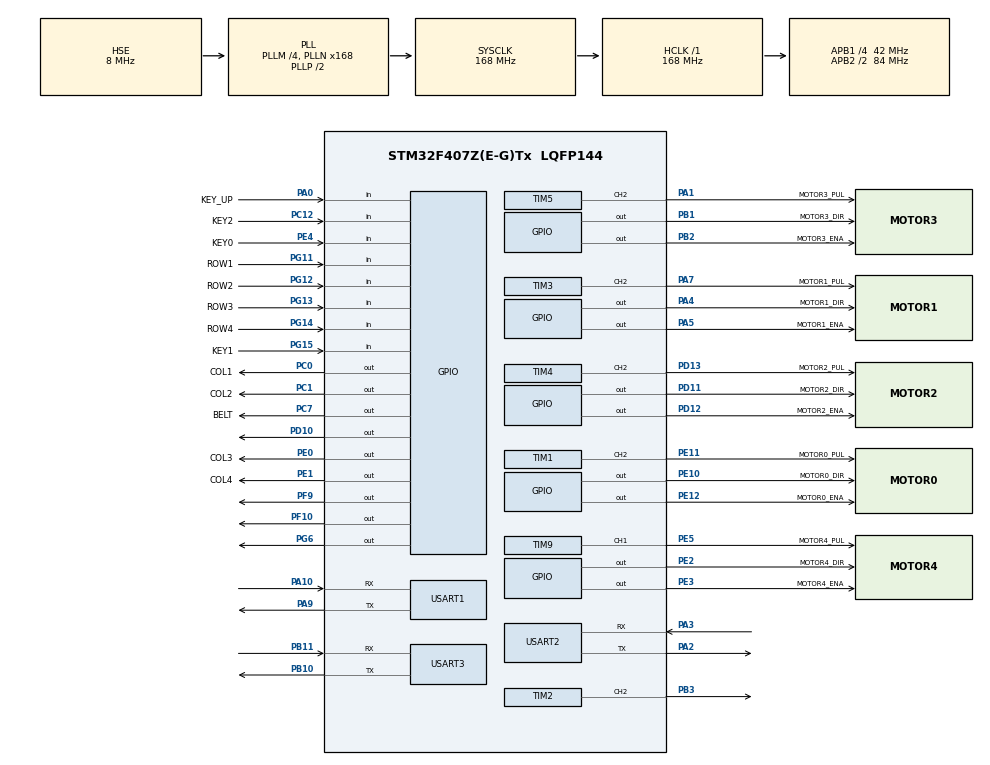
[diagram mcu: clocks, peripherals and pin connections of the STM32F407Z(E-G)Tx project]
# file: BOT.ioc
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Dma.Request0=USART1_RX
Dma.Request1=USART1_TX
Dma.Request2=USART2_RX
Dma.Request3=USART2_TX
Dma.Request4=USART3_RX
Dma.Request5=USART3_TX
Dma.USART1_RX.0.Direction=DMA_PERIPH_TO_MEMORY
Dma.USART1_RX.0.FIFOMode=DMA_FIFOMODE_DISABLE
Dma.USART1_RX.0.Instance=DMA2_Stream2
Dma.USART1_RX.0.MemDataAlignment=DMA_MDATAALIGN_BYTE
Dma.USART1_RX.0.MemInc=DMA_MINC_ENABLE
Dma.USART1_RX.0.Mode=DMA_CIRCULAR
Dma.USART1_RX.0.PeriphDataAlignment=DMA_PDATAALIGN_BYTE
Dma.USART1_RX.0.PeriphInc=DMA_PINC_DISABLE
Dma.USART1_RX.0.Priority=DMA_PRIORITY_VERY_HIGH
Dma.USART1_TX.1.Direction=DMA_MEMORY_TO_PERIPH
Dma.USART1_TX.1.FIFOMode=DMA_FIFOMODE_DISABLE
Dma.USART1_TX.1.Instance=DMA2_Stream7
Dma.USART1_TX.1.MemDataAlignment=DMA_MDATAALIGN_BYTE
Dma.USART1_TX.1.MemInc=DMA_MINC_ENABLE
Dma.USART1_TX.1.Mode=DMA_NORMAL
Dma.USART1_TX.1.PeriphDataAlignment=DMA_PDATAALIGN_BYTE
Dma.USART1_TX.1.PeriphInc=DMA_PINC_DISABLE
Dma.USART1_TX.1.Priority=DMA_PRIORITY_VERY_HIGH
Dma.USART2_RX.2.Direction=DMA_PERIPH_TO_MEMORY
Dma.USART2_RX.2.FIFOMode=DMA_FIFOMODE_DISABLE
Dma.USART2_RX.2.Instance=DMA1_Stream5
Dma.USART2_RX.2.MemDataAlignment=DMA_MDATAALIGN_BYTE
Dma.USART2_RX.2.MemInc=DMA_MINC_ENABLE
Dma.USART2_RX.2.Mode=DMA_NORMAL
Dma.USART2_RX.2.PeriphDataAlignment=DMA_PDATAALIGN_BYTE
Dma.USART2_RX.2.PeriphInc=DMA_PINC_DISABLE
Dma.USART2_RX.2.Priority=DMA_PRIORITY_HIGH
Dma.USART2_TX.3.Direction=DMA_MEMORY_TO_PERIPH
Dma.USART2_TX.3.FIFOMode=DMA_FIFOMODE_DISABLE
Dma.USART2_TX.3.Instance=DMA1_Stream6
Dma.USART2_TX.3.MemDataAlignment=DMA_MDATAALIGN_BYTE
Dma.USART2_TX.3.MemInc=DMA_MINC_ENABLE
Dma.USART2_TX.3.Mode=DMA_NORMAL
Dma.USART2_TX.3.PeriphDataAlignment=DMA_PDATAALIGN_BYTE
Dma.USART2_TX.3.PeriphInc=DMA_PINC_DISABLE
Dma.USART2_TX.3.Priority=DMA_PRIORITY_HIGH
Dma.USART3_RX.4.Direction=DMA_PERIPH_TO_MEMORY
Dma.USART3_RX.4.FIFOMode=DMA_FIFOMODE_DISABLE
Dma.USART3_RX.4.Instance=DMA1_Stream1
Dma.USART3_RX.4.MemDataAlignment=DMA_MDATAALIGN_BYTE
Dma.USART3_RX.4.MemInc=DMA_MINC_ENABLE
Dma.USART3_RX.4.Mode=DMA_NORMAL
Dma.USART3_RX.4.PeriphDataAlignment=DMA_PDATAALIGN_BYTE
Dma.USART3_RX.4.PeriphInc=DMA_PINC_DISABLE
Dma.USART3_RX.4.Priority=DMA_PRIORITY_MEDIUM
Dma.USART3_TX.5.Direction=DMA_MEMORY_TO_PERIPH
Dma.USART3_TX.5.FIFOMode=DMA_FIFOMODE_DISABLE
Dma.USART3_TX.5.Instance=DMA1_Stream3
Dma.USART3_TX.5.MemDataAlignment=DMA_MDATAALIGN_BYTE
Dma.USART3_TX.5.MemInc=DMA_MINC_ENABLE
Dma.USART3_TX.5.Mode=DMA_NORMAL
Dma.USART3_TX.5.PeriphDataAlignment=DMA_PDATAALIGN_BYTE
Dma.USART3_TX.5.PeriphInc=DMA_PINC_DISABLE
Dma.USART3_TX.5.Priority=DMA_PRIORITY_MEDIUM
Mcu.Family=STM32F4
Mcu.Name=STM32F407Z(E-G)Tx
Mcu.Package=LQFP144
NVIC.DMA1_Stream1_IRQn=true\:0\:0\:false\:false\:true\:false\:true\:true
NVIC.DMA1_Stream3_IRQn=true\:0\:0\:false\:false\:true\:false\:true\:true
NVIC.DMA1_Stream5_IRQn=true\:0\:0\:false\:false\:true\:false\:true\:true
NVIC.DMA1_Stream6_IRQn=true\:0\:0\:false\:false\:true\:false\:true\:true
NVIC.DMA2_Stream2_IRQn=true\:0\:0\:false\:false\:true\:false\:true\:true
NVIC.DMA2_Stream7_IRQn=true\:0\:0\:false\:false\:true\:false\:true\:true
NVIC.PriorityGroup=NVIC_PRIORITYGROUP_4
NVIC.TIM1_BRK_TIM9_IRQn=true\:0\:0\:false\:false\:true\:true\:true\:true
NVIC.TIM1_CC_IRQn=true\:0\:0\:false\:false\:true\:true\:true\:true
NVIC.TIM1_TRG_COM_TIM11_IRQn=true\:0\:0\:false\:false\:true\:true\:true\:true
NVIC.TIM1_UP_TIM10_IRQn=true\:0\:0\:false\:false\:true\:true\:true\:true
NVIC.TIM2_IRQn=true\:0\:0\:false\:false\:true\:true\:true\:true
NVIC.TIM3_IRQn=true\:0\:0\:false\:false\:true\:true\:true\:true
NVIC.TIM4_IRQn=true\:0\:0\:false\:false\:true\:true\:true\:true
NVIC.TIM5_IRQn=true\:0\:0\:false\:false\:true\:true\:true\:true
NVIC.USART1_IRQn=true\:0\:0\:false\:false\:true\:true\:true\:true
NVIC.USART2_IRQn=true\:0\:0\:false\:false\:true\:true\:true\:true
NVIC.USART3_IRQn=true\:0\:0\:false\:false\:true\:true\:true\:true
PA0-WKUP.GPIO_Label=KEY_UP
PA0-WKUP.GPIO_PuPd=GPIO_PULLDOWN
PA0-WKUP.Signal=GPIO_Input
PA1.GPIO_Label=MOTOR3_PUL
PA1.Signal=S_TIM5_CH2
PA10.Mode=Asynchronous
PA10.Signal=USART1_RX
PA2.Mode=Asynchronous
PA2.Signal=USART2_TX
PA3.Mode=Asynchronous
PA3.Signal=USART2_RX
PA4.GPIO_Label=MOTOR1_DIR
PA4.GPIO_Speed=GPIO_SPEED_FREQ_LOW
PA4.Signal=GPIO_Output
PA5.GPIO_Label=MOTOR1_ENA
PA5.Signal=GPIO_Output
PA7.GPIO_Label=MOTOR1_PUL
PA7.Signal=S_TIM3_CH2
PA9.Mode=Asynchronous
PA9.Signal=USART1_TX
PB1.GPIO_Label=MOTOR3_DIR
PB1.Signal=GPIO_Output
PB10.Mode=Asynchronous
PB10.Signal=USART3_TX
PB11.Mode=Asynchronous
PB11.Signal=USART3_RX
PB2.GPIO_Label=MOTOR3_ENA
PB2.Signal=GPIO_Output
PB3.Signal=S_TIM2_CH2
PC0.GPIO_Label=COL1
PC0.GPIO_Speed=GPIO_SPEED_FREQ_HIGH
PC0.Signal=GPIO_Output
PC1.GPIO_Label=COL2
PC1.GPIO_Speed=GPIO_SPEED_FREQ_HIGH
PC1.Signal=GPIO_Output
PC12.GPIO_Label=KEY2
PC12.Signal=GPIO_Input
PC7.GPIO_Label=BELT
PC7.Signal=GPIO_Output
PD10.Signal=GPIO_Output
PD11.GPIO_Label=MOTOR2_DIR
PD11.Signal=GPIO_Output
PD12.GPIO_Label=MOTOR2_ENA
PD12.Signal=GPIO_Output
PD13.GPIO_Label=MOTOR2_PUL
PD13.Signal=S_TIM4_CH2
PE0.GPIO_Label=COL3
PE0.GPIO_Speed=GPIO_SPEED_FREQ_HIGH
PE0.Signal=GPIO_Output
PE1.GPIO_Label=COL4
PE1.GPIO_Speed=GPIO_SPEED_FREQ_HIGH
PE1.Signal=GPIO_Output
PE10.GPIO_Label=MOTOR0_DIR
PE10.Signal=GPIO_Output
PE11.GPIO_Label=MOTOR0_PUL
PE11.Signal=S_TIM1_CH2
PE12.GPIO_Label=MOTOR0_ENA
PE12.Signal=GPIO_Output
PE2.GPIO_Label=MOTOR4_DIR
PE2.Signal=GPIO_Output
PE3.GPIO_Label=MOTOR4_ENA
PE3.Signal=GPIO_Output
PE4.GPIO_Label=KEY0
PE4.Signal=GPIO_Input
PE5.GPIO_Label=MOTOR4_PUL
PE5.Signal=S_TIM9_CH1
PF10.GPIO_Speed=GPIO_SPEED_FREQ_HIGH
PF10.PinState=GPIO_PIN_SET
PF10.Signal=GPIO_Output
PF9.GPIO_Speed=GPIO_SPEED_FREQ_HIGH
PF9.PinState=GPIO_PIN_SET
PF9.Signal=GPIO_Output
PG11.GPIO_Label=ROW1
PG11.Signal=GPIO_Input
PG12.GPIO_Label=ROW2
PG12.Signal=GPIO_Input
PG13.GPIO_Label=ROW3
PG13.Signal=GPIO_Input
PG14.GPIO_Label=ROW4
PG14.Signal=GPIO_Input
PG15.GPIO_Label=KEY1
PG15.Signal=GPIO_Input
PG6.Signal=GPIO_Output
PH0-OSC_IN.Mode=HSE-External-Oscillator
PH0-OSC_IN.Signal=RCC_OSC_IN
PH1-OSC_OUT.Mode=HSE-External-Oscillator
PH1-OSC_OUT.Signal=RCC_OSC_OUT
ProjectManager.HeapSize=0x200
ProjectManager.StackSize=0x400
ProjectManager.TargetToolchain=MDK-ARM V5.32
RCC.48MHZClocksFreq_Value=84000000
RCC.AHBFreq_Value=168000000
RCC.APB1CLKDivider=RCC_HCLK_DIV4
RCC.APB1Freq_Value=42000000
RCC.APB1TimFreq_Value=84000000
RCC.APB2CLKDivider=RCC_HCLK_DIV2
RCC.APB2Freq_Value=84000000
RCC.APB2TimFreq_Value=168000000
RCC.CortexFreq_Value=168000000
RCC.EnbaleCSS=true
RCC.HCLKFreq_Value=168000000
RCC.HSE_VALUE=8000000
RCC.HSI_VALUE=16000000
RCC.LSE_VALUE=32768
RCC.PLLM=4
RCC.PLLN=168
RCC.PLLSourceVirtual=RCC_PLLSOURCE_HSE
RCC.SYSCLKFreq_VALUE=168000000
RCC.SYSCLKSource=RCC_SYSCLKSOURCE_PLLCLK
RCC.VCOOutputFreq_Value=336000000
SH.S_TIM1_CH2.0=TIM1_CH2,PWM Generation2 CH2
SH.S_TIM2_CH2.0=TIM2_CH2,Output Compare2 CH2
SH.S_TIM3_CH2.0=TIM3_CH2,PWM Generation2 CH2
SH.S_TIM4_CH2.0=TIM4_CH2,Output Compare2 CH2
SH.S_TIM5_CH2.0=TIM5_CH2,Output Compare2 CH2
SH.S_TIM9_CH1.0=TIM9_CH1,PWM Generation1 CH1
TIM1.Channel-PWM\ Generation2\ CH2=TIM_CHANNEL_2
TIM2.Channel-Output\ Compare2\ CH2=TIM_CHANNEL_2
TIM2.Period=8000000
TIM2.Prescaler=1000
TIM3.Channel-PWM\ Generation2\ CH2=TIM_CHANNEL_2
TIM3.Prescaler=1000
TIM4.Channel-Output\ Compare2\ CH2=TIM_CHANNEL_2
TIM5.Channel-Output\ Compare2\ CH2=TIM_CHANNEL_2
TIM9.Channel-PWM\ Generation1\ CH1=TIM_CHANNEL_1
USART1.VirtualMode=VM_ASYNC
USART2.VirtualMode=VM_ASYNC
USART3.VirtualMode=VM_ASYNC
VP_TIM1_VS_ClockSourceINT.Mode=Internal
VP_TIM2_VS_ClockSourceINT.Mode=Internal
VP_TIM3_VS_ClockSourceINT.Mode=Internal
VP_TIM4_VS_ClockSourceINT.Mode=Internal
VP_TIM5_VS_ClockSourceINT.Mode=Internal
VP_TIM9_VS_ClockSourceINT.Mode=Internal
board=custom

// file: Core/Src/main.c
/* USER CODE BEGIN Header */
/**
  ******************************************************************************
  * @file           : main.c
  * @brief          : Main program body
  ******************************************************************************
  * @attention
  *
  * Copyright (c) 2025 STMicroelectronics.
  * All rights reserved.
  *
  * This software is licensed under terms that can be found in the LICENSE file
  * in the root directory of this software component.
  * If no LICENSE file comes with this software, it is provided AS-IS.
  *
  ******************************************************************************
  */
/* USER CODE END Header */
#include "main.h"
#include "dma.h"
#include "tim.h"
#include "usart.h"
#include "gpio.h"

/* USER CODE BEGIN Includes */
#include "servoMotor.h"
#include "stepMotor.h"
#include "key.h"
#include "led.h"
#include "delay.h"
#include "string.h"
#include "identify.h"
#include "task.c"
#include "motor.h"
/* USER CODE END Includes */

void SystemClock_Config(void);

int main(void)
{

  /* MCU Configuration--------------------------------------------------------*/

  /* Reset of all peripherals, Initializes the Flash interface and the Systick. */
  HAL_Init();

  /* Configure the system clock */
  SystemClock_Config();

  /* Initialize all configured peripherals */
  MX_GPIO_Init();
  MX_DMA_Init();
  MX_TIM1_Init();
  MX_TIM2_Init();
  MX_TIM3_Init();
  MX_TIM4_Init();
  MX_TIM5_Init();
  MX_TIM9_Init();
  MX_USART1_UART_Init();
  MX_USART2_UART_Init();
  MX_USART3_UART_Init();
  /* USER CODE BEGIN 2 */
/* USER CODE BEGIN 2 */

  /* USER CODE END 2 */

  /* Infinite loop */
  /* USER CODE BEGIN WHILE */
  while (1)
  {
   // Adjust the parameters as needed
   Turn(1, 10000); // Reduced value to fit into 16-bit integer, adjust as needed
		// ...existing code...
// MX_TIM3_Init();
// HAL_TIM_PWM_Start(&htim3, TIM_CHANNEL_2);
// __HAL_TIM_SET_COMPARE(&htim3, TIM_CHANNEL_2, 500); // 假设Period=1000，占空比50%
// ...existing code...
    // catchServoMotor();
    // delay_ms(1000);
    // releaseServoMotor();
    // delay_ms(1000);
    //HAL_GPIO_WritePin(GPIOC, GPIO_PIN_7, GPIO_PIN_RESET);
    // if(HAL_GPIO_ReadPin(GPIOC, GPIO_PIN_12) == GPIO_PIN_RESET){
    //   HAL_GPIO_WritePin(GPIOD, GPIO_PIN_10, GPIO_PIN_RESET);
    // delay_ms(500);
    // HAL_GPIO_WritePin(GPIOD, GPIO_PIN_10, GPIO_PIN_SET);
    // delay_ms(500);
    //  HAL_GPIO_WritePin(GPIOG, GPIO_PIN_6, GPIO_PIN_RESET);
    // delay_ms(500);
    // HAL_GPIO_WritePin(GPIOG, GPIO_PIN_6, GPIO_PIN_SET);
    // delay_ms(500);

    // }
    // if(HAL_GPIO_ReadPin(GPIOG, GPIO_PIN_15) == GPIO_PIN_RESET){

    //    HAL_GPIO_WritePin(GPIOD, GPIO_PIN_10, GPIO_PIN_RESET);
    // delay_ms(500);
    // HAL_GPIO_WritePin(GPIOD, GPIO_PIN_10, GPIO_PIN_SET);
    // delay_ms(500);
    //  HAL_GPIO_WritePin(GPIOG, GPIO_PIN_6, GPIO_PIN_RESET);
    // delay_ms(500);
    // HAL_GPIO_WritePin(GPIOG, GPIO_PIN_6, GPIO_PIN_SET);
    // delay_ms(500);

    // HAL_GPIO_WritePin(GPIOA, GPIO_PIN_7, GPIO_PIN_SET);
    // HAL_Delay(1000);
    // HAL_GPIO_WritePin(GPIOA, GPIO_PIN_7, GPIO_PIN_RESET);
    // HAL_Delay(1000);

	//}
  }
    /* USER CODE END WHILE */

}

void SystemClock_Config(void)
{
  RCC_OscInitTypeDef RCC_OscInitStruct = {0};
  RCC_ClkInitTypeDef RCC_ClkInitStruct = {0};

  /** Configure the main internal regulator output voltage
  */
  __HAL_RCC_PWR_CLK_ENABLE();
  __HAL_PWR_VOLTAGESCALING_CONFIG(PWR_REGULATOR_VOLTAGE_SCALE1);

  /** Initializes the RCC Oscillators according to the specified parameters
  * in the RCC_OscInitTypeDef structure.
  */
  RCC_OscInitStruct.OscillatorType = RCC_OSCILLATORTYPE_HSE;
  RCC_OscInitStruct.HSEState = RCC_HSE_ON;
  RCC_OscInitStruct.PLL.PLLState = RCC_PLL_ON;
  RCC_OscInitStruct.PLL.PLLSource = RCC_PLLSOURCE_HSE;
  RCC_OscInitStruct.PLL.PLLM = 4;
  RCC_OscInitStruct.PLL.PLLN = 168;
  RCC_OscInitStruct.PLL.PLLP = RCC_PLLP_DIV2;
  RCC_OscInitStruct.PLL.PLLQ = 4;
  if (HAL_RCC_OscConfig(&RCC_OscInitStruct) != HAL_OK)
  {
    Error_Handler();
  }

  /** Initializes the CPU, AHB and APB buses clocks
  */
  RCC_ClkInitStruct.ClockType = RCC_CLOCKTYPE_HCLK|RCC_CLOCKTYPE_SYSCLK
                              |RCC_CLOCKTYPE_PCLK1|RCC_CLOCKTYPE_PCLK2;
  RCC_ClkInitStruct.SYSCLKSource = RCC_SYSCLKSOURCE_PLLCLK;
  RCC_ClkInitStruct.AHBCLKDivider = RCC_SYSCLK_DIV1;
  RCC_ClkInitStruct.APB1CLKDivider = RCC_HCLK_DIV4;
  RCC_ClkInitStruct.APB2CLKDivider = RCC_HCLK_DIV2;

  if (HAL_RCC_ClockConfig(&RCC_ClkInitStruct, FLASH_LATENCY_5) != HAL_OK)
  {
    Error_Handler();
  }

  /** Enables the Clock Security System
  */
  HAL_RCC_EnableCSS();
}

/* USER CODE BEGIN 4 */
/* USER CODE BEGIN 4 */

/* USER CODE END 4 */

void Error_Handler(void)
{
  __disable_irq();
  while (1)
  {
  }
}
